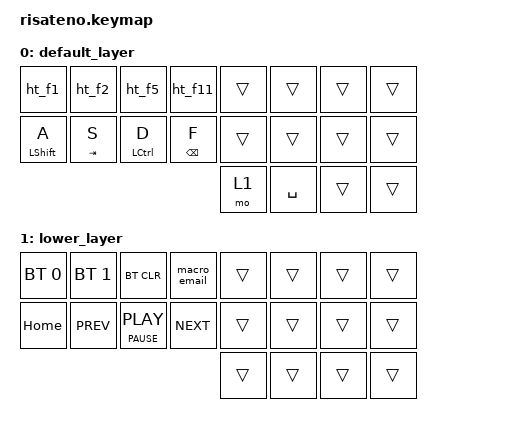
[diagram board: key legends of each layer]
#include <behaviors.dtsi>
#include <dt-bindings/zmk/bt.h>
#include <dt-bindings/zmk/keys.h>
#include <dt-bindings/zmk/outputs.h>
#include <dt-bindings/zmk/ext_power.h>

// CONFIG
#define COMBO_TIMEOUT 90
#define COMBO_LAYERS 0 1

// LAYERS
#define DEFAULT 0
#define LOWER   1
// LEFT SIDE
#define TLP 0 // TOP
#define TLR 1 // TOP
#define TLM 2 // TOP
#define TLI 3 // TOP
#define BLP 4 // BOTTOM
#define BLR 5 // BOTTOM
#define BLM 6 // BOTTOM
#define BLI 7 // BOTTOM
#define LOT 8 // O-THUMB
#define LIT 9 // I-THUMB

// RIGHT SIDE
#define TRP 10 // TOP
#define TRR 11 // TOP
#define TRM 12 // TOP
#define TRI 13 // TOP
#define BRP 14 // BOTTOM
#define BRR 15 // BOTTOM
#define BRM 16 // BOTTOM
#define BRI 17 // BOTTOM
#define ROT 18 // O-THUMB
#define RIT 19 // I-THUMB

/ {
    behaviors {
        ht_s_tab: hold_tap_s_tab {
            compatible = "zmk,behavior-hold-tap";
            #binding-cells = <2>;
            tapping-term-ms = <180>;
            flavor = "tap-preferred";
            bindings = <&kp>, <&kp>;
        };

        ht_f_del: hold_tap_f_del {
            compatible = "zmk,behavior-hold-tap";
            #binding-cells = <2>;
            tapping-term-ms = <180>;
            flavor = "tap-preferred";
            bindings = <&kp>, <&kp>;
        };

        macro_email: macro_email {
            compatible = "zmk,behavior-macro";
            #binding-cells = <0>;
            bindings = <
                &kp T &kp I &kp R &kp E &kp J &kp K &kp I &kp N &kp A
                &kp N0 &kp N0 &kp N5 &kp AT
                &kp G &kp M &kp A &kp I &kp L &kp DOT
                &kp C &kp O &kp M
            >;
        };
        ht_media_play: hold_tap_media_play {
        compatible = "zmk,behavior-hold-tap";
        #binding-cells = <2>;
        tapping-term-ms = <180>;
        flavor = "tap-preferred";
        bindings = <&kp>, <&kp>;
        };

        ht_f1: ht_f1 {
            compatible = "zmk,behavior-hold-tap";
            #binding-cells = <2>;
            tapping-term-ms = <250>;
            flavor = "hold-preferred";
            bindings = <&kp F1>, <&kp Z>;  
        };

        ht_f2: ht_f2 {
            compatible = "zmk,behavior-hold-tap";
            #binding-cells = <2>;
            tapping-term-ms = <250>;
            flavor = "hold-preferred";
            bindings = <&kp F2>, <&kp X>;
        };

        ht_f5: ht_f5 {
            compatible = "zmk,behavior-hold-tap";
            #binding-cells = <2>;
            tapping-term-ms = <250>;
            flavor = "hold-preferred";
            bindings = <&kp F5>, <&kp C>;
        };

        ht_f11: ht_f11 {
            compatible = "zmk,behavior-hold-tap";
            #binding-cells = <2>;
            tapping-term-ms = <250>;
            flavor = "hold-preferred";
            bindings = <&kp F11>, <&kp V>;
    };

    combos {
        compatible = "zmk,combos";
        #include "chords.dtsi"
    };



 keymap {
    compatible = "zmk,keymap";

    default_layer {
    // Левая рука                   |  Правая рука
    // | TLP | TLR | TLM | TLI |   | TRI | TRM | TRR | TRP |
    // | BLP | BLR | BLM | BLI |   | BRI | BRM | BRR | BRP |
    //             | LOT | LIT |   | RIT | ROT |
      bindings = <
         &ht_f1   &ht_f2   &ht_f5   &ht_f11        &trans &trans &trans &trans
         &mt LSHIFT A &ht_s_tab TAB S  &mt LCTRL D &ht_f_del BSPC F &trans &trans &trans &trans
                                               &mo 1 &kp SPACE   &trans &trans
      >;
    };
    lower_layer {
        bindings = <
        &bt BT_SEL 0  &bt BT_SEL 1  &bt BT_CLR &macro_email              &trans &trans &trans &trans
        &kp HOME &kp C_PREV &ht_media_play C_PAUSE C_PLAY &kp C_NEXT       &trans &trans &trans &trans 
                          &trans &trans        &trans &trans
      >;
    };
  };
};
